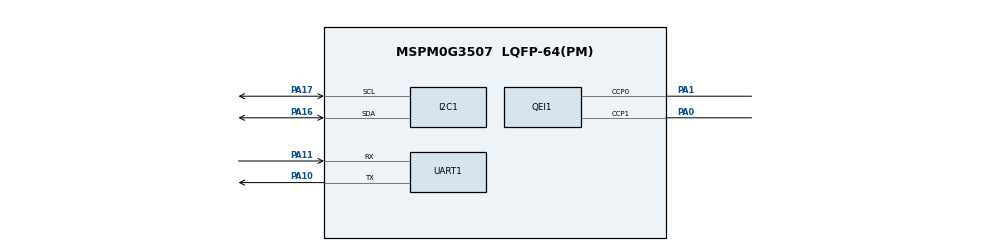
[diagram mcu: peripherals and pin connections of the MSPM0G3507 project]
/**
 * These arguments were used when this file was generated. They will be automatically applied on subsequent loads
 * via the GUI or CLI. Run CLI with '--help' for additional information on how to override these arguments.
 * @cliArgs --device "MSPM0G350X" --part "Default" --package "LQFP-64(PM)" --product "mspm0_sdk@2.02.00.05"
 * @v2CliArgs --device "MSPM0G3507" --package "LQFP-64(PM)" --product "mspm0_sdk@2.02.00.05"
 * @versions {"tool":"1.21.1+3772"}
 */

/**
 * Import the modules used in this configuration.
 */
const GPIO    = scripting.addModule("/ti/driverlib/GPIO", {}, false);
const GPIO1   = GPIO.addInstance();
const GPIO2   = GPIO.addInstance();
const I2C     = scripting.addModule("/ti/driverlib/I2C", {}, false);
const I2C1    = I2C.addInstance();
const PWM     = scripting.addModule("/ti/driverlib/PWM", {}, false);
const PWM1    = PWM.addInstance();
const PWM2    = PWM.addInstance();
const QEI     = scripting.addModule("/ti/driverlib/QEI", {}, false);
const QEI1    = QEI.addInstance();
const SYSCTL  = scripting.addModule("/ti/driverlib/SYSCTL");
const SYSTICK = scripting.addModule("/ti/driverlib/SYSTICK");
const UART    = scripting.addModule("/ti/driverlib/UART", {}, false);
const UART1   = UART.addInstance();

/**
 * Write custom configuration values to the imported modules.
 */
GPIO1.$name                              = "ENCODER_B";
GPIO1.port                               = "PORTA";
GPIO1.portSegment                        = "Lower";
GPIO1.associatedPins.create(2);
GPIO1.associatedPins[0].$name            = "PHASE_A";
GPIO1.associatedPins[0].direction        = "INPUT";
GPIO1.associatedPins[0].assignedPin      = "8";
GPIO1.associatedPins[0].interruptEn      = true;
GPIO1.associatedPins[0].polarity         = "RISE_FALL";
GPIO1.associatedPins[0].internalResistor = "PULL_UP";
GPIO1.associatedPins[0].inputFilter      = "3_CYCLES";
GPIO1.associatedPins[1].$name            = "PHASE_B";
GPIO1.associatedPins[1].direction        = "INPUT";
GPIO1.associatedPins[1].assignedPin      = "9";
GPIO1.associatedPins[1].interruptEn      = true;
GPIO1.associatedPins[1].polarity         = "RISE_FALL";
GPIO1.associatedPins[1].internalResistor = "PULL_UP";
GPIO1.associatedPins[1].inputFilter      = "3_CYCLES";

const Board = scripting.addModule("/ti/driverlib/Board", {}, false);

GPIO2.$name                              = "GRAY_6CH";
GPIO2.port                               = "PORTA";
GPIO2.associatedPins.create(6);
GPIO2.associatedPins[0].$name            = "GRAY_L2";
GPIO2.associatedPins[0].direction        = "INPUT";
GPIO2.associatedPins[0].internalResistor = "PULL_UP";
GPIO2.associatedPins[0].assignedPin      = "24";
GPIO2.associatedPins[1].$name            = "GRAY_L1";
GPIO2.associatedPins[1].direction        = "INPUT";
GPIO2.associatedPins[1].assignedPin      = "25";
GPIO2.associatedPins[1].internalResistor = "PULL_UP";
GPIO2.associatedPins[2].$name            = "GRAY_M1";
GPIO2.associatedPins[2].direction        = "INPUT";
GPIO2.associatedPins[2].internalResistor = "PULL_UP";
GPIO2.associatedPins[2].assignedPin      = "26";
GPIO2.associatedPins[3].$name            = "GRAY_M2";
GPIO2.associatedPins[3].direction        = "INPUT";
GPIO2.associatedPins[3].internalResistor = "PULL_UP";
GPIO2.associatedPins[3].assignedPin      = "27";
GPIO2.associatedPins[4].$name            = "GRAY_R1";
GPIO2.associatedPins[4].direction        = "INPUT";
GPIO2.associatedPins[4].internalResistor = "PULL_UP";
GPIO2.associatedPins[4].assignedPin      = "28";
GPIO2.associatedPins[5].$name            = "GRAY_R2";
GPIO2.associatedPins[5].direction        = "INPUT";
GPIO2.associatedPins[5].assignedPin      = "29";
GPIO2.associatedPins[5].internalResistor = "PULL_UP";

I2C1.$name                     = "I2C_0";
I2C1.basicEnableController     = true;
I2C1.peripheral.$assign        = "I2C1";
I2C1.peripheral.sdaPin.$assign = "PA16";
I2C1.peripheral.sclPin.$assign = "PA17";
I2C1.sdaPinConfig.$name        = "ti_driverlib_gpio_GPIOPinGeneric6";
I2C1.sdaPinConfig.enableConfig = true;
I2C1.sdaPinConfig.internalResistor = "PULL_UP";
I2C1.sclPinConfig.$name        = "ti_driverlib_gpio_GPIOPinGeneric7";
I2C1.sclPinConfig.enableConfig = true;
I2C1.sclPinConfig.internalResistor = "PULL_UP";

PWM1.timerStartTimer                    = true;
PWM1.pwmMode                            = "EDGE_ALIGN_UP";
PWM1.timerCount                         = 2399;
PWM1.$name                              = "PWM_AIN";
PWM1.peripheral.$assign                 = "TIMG0";
PWM1.PWM_CHANNEL_0.$name                = "ti_driverlib_pwm_PWMTimerCC0";
PWM1.PWM_CHANNEL_1.$name                = "ti_driverlib_pwm_PWMTimerCC2";
PWM1.ccp0PinConfig.direction            = scripting.forceWrite("OUTPUT");
PWM1.ccp0PinConfig.hideOutputInversion  = scripting.forceWrite(false);
PWM1.ccp0PinConfig.onlyInternalResistor = scripting.forceWrite(false);
PWM1.ccp0PinConfig.passedPeripheralType = scripting.forceWrite("Digital");
PWM1.ccp0PinConfig.$name                = "ti_driverlib_gpio_GPIOPinGeneric2";
PWM1.ccp1PinConfig.direction            = scripting.forceWrite("OUTPUT");
PWM1.ccp1PinConfig.hideOutputInversion  = scripting.forceWrite(false);
PWM1.ccp1PinConfig.onlyInternalResistor = scripting.forceWrite(false);
PWM1.ccp1PinConfig.passedPeripheralType = scripting.forceWrite("Digital");
PWM1.ccp1PinConfig.$name                = "ti_driverlib_gpio_GPIOPinGeneric0";

PWM2.timerStartTimer                    = true;
PWM2.pwmMode                            = "EDGE_ALIGN_UP";
PWM2.timerCount                         = 2399;
PWM2.$name                              = "PWM_BIN";
PWM2.peripheral.$assign                 = "TIMG6";
PWM2.PWM_CHANNEL_0.$name                = "ti_driverlib_pwm_PWMTimerCC0_COPY";
PWM2.PWM_CHANNEL_1.$name                = "ti_driverlib_pwm_PWMTimerCC2_COPY";
PWM2.ccp0PinConfig.direction            = scripting.forceWrite("OUTPUT");
PWM2.ccp0PinConfig.hideOutputInversion  = scripting.forceWrite(false);
PWM2.ccp0PinConfig.onlyInternalResistor = scripting.forceWrite(false);
PWM2.ccp0PinConfig.passedPeripheralType = scripting.forceWrite("Digital");
PWM2.ccp0PinConfig.$name                = "ti_driverlib_gpio_GPIOPinGeneric2_COPY";
PWM2.ccp1PinConfig.direction            = scripting.forceWrite("OUTPUT");
PWM2.ccp1PinConfig.hideOutputInversion  = scripting.forceWrite(false);
PWM2.ccp1PinConfig.onlyInternalResistor = scripting.forceWrite(false);
PWM2.ccp1PinConfig.passedPeripheralType = scripting.forceWrite("Digital");
PWM2.ccp1PinConfig.$name                = "ti_driverlib_gpio_GPIOPinGeneric0_COPY";

QEI1.$name                              = "ENCODER_A";
QEI1.timerStartTimer                    = true;
QEI1.peripheral.$assign                 = "TIMG8";
QEI1.peripheral.ccp0Pin.$assign         = "PA1";
QEI1.peripheral.ccp1Pin.$assign         = "PA0";
QEI1.ccp0PinConfig.hideOutputInversion  = scripting.forceWrite(false);
QEI1.ccp0PinConfig.onlyInternalResistor = scripting.forceWrite(false);
QEI1.ccp0PinConfig.passedPeripheralType = scripting.forceWrite("Digital");
QEI1.ccp0PinConfig.$name                = "ti_driverlib_gpio_GPIOPinGeneric1";
QEI1.ccp1PinConfig.hideOutputInversion  = scripting.forceWrite(false);
QEI1.ccp1PinConfig.onlyInternalResistor = scripting.forceWrite(false);
QEI1.ccp1PinConfig.passedPeripheralType = scripting.forceWrite("Digital");
QEI1.ccp1PinConfig.$name                = "ti_driverlib_gpio_GPIOPinGeneric3";

SYSCTL.forceDefaultClkConfig = true;

SYSTICK.periodEnable  = true;
SYSTICK.systickEnable = true;
SYSTICK.period        = 320000;

UART1.$name                            = "DEBUG_UART";
UART1.targetBaudRate                   = 115200;
UART1.peripheral.$assign               = "UART0";
UART1.peripheral.rxPin.$assign         = "PA11";
UART1.peripheral.txPin.$assign         = "PA10";
UART1.txPinConfig.direction            = scripting.forceWrite("OUTPUT");
UART1.txPinConfig.hideOutputInversion  = scripting.forceWrite(false);
UART1.txPinConfig.onlyInternalResistor = scripting.forceWrite(false);
UART1.txPinConfig.passedPeripheralType = scripting.forceWrite("Digital");
UART1.txPinConfig.$name                = "ti_driverlib_gpio_GPIOPinGeneric4";
UART1.rxPinConfig.hideOutputInversion  = scripting.forceWrite(false);
UART1.rxPinConfig.onlyInternalResistor = scripting.forceWrite(false);
UART1.rxPinConfig.passedPeripheralType = scripting.forceWrite("Digital");
UART1.rxPinConfig.$name                = "ti_driverlib_gpio_GPIOPinGeneric5";

/**
 * Pinmux solution for unlocked pins/peripherals. This ensures that minor changes to the automatic solver in a future
 * version of the tool will not impact the pinmux you originally saw.  These lines can be completely deleted in order to
 * re-solve from scratch.
 */
GPIO1.associatedPins[0].pin.$suggestSolution = "PA8";
GPIO1.associatedPins[1].pin.$suggestSolution = "PA9";
Board.peripheral.$suggestSolution            = "DEBUGSS";
Board.peripheral.swclkPin.$suggestSolution   = "PA20";
Board.peripheral.swdioPin.$suggestSolution   = "PA19";
GPIO2.associatedPins[0].pin.$suggestSolution = "PA24";
GPIO2.associatedPins[1].pin.$suggestSolution = "PA25";
GPIO2.associatedPins[2].pin.$suggestSolution = "PA26";
GPIO2.associatedPins[3].pin.$suggestSolution = "PA27";
GPIO2.associatedPins[4].pin.$suggestSolution = "PA28";
GPIO2.associatedPins[5].pin.$suggestSolution = "PA29";
PWM1.peripheral.ccp0Pin.$suggestSolution     = "PA12";
PWM1.peripheral.ccp1Pin.$suggestSolution     = "PA13";
PWM2.peripheral.ccp0Pin.$suggestSolution     = "PA21";
PWM2.peripheral.ccp1Pin.$suggestSolution     = "PA22";
SYSCTL.peripheral.$suggestSolution           = "SYSCTL";
